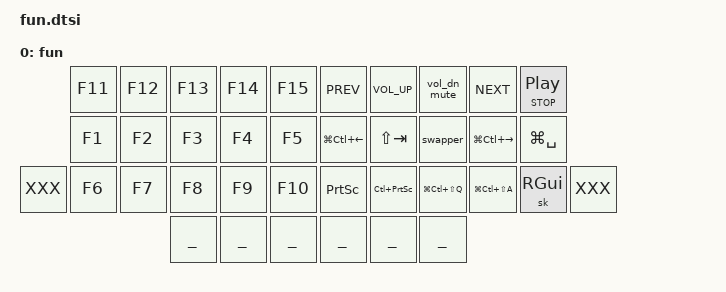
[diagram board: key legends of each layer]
/**
 * Function / System Layer
 */

// Misc aliases
#define DSK_MGR  &kp LG(SPACE)
#define DSK_PREV &kp LG(LC(LEFT))
#define DSK_NEXT &kp LG(LC(RIGHT))
#define PIN_WIN  &kp LG(LC(LS(Q)))
#define PIN_APP  &kp LG(LC(LS(A)))

/ {
    keymap {
        compatible = "zmk,keymap";
  
        fun {
            display-name = "fun";
            bindings = <
//                ╭─────────────┬─────────────┬─────────────┬─────────────┬─────────────╮   ╭─────────────┬─────────────┬─────────────┬─────────────┬─────────────╮
                   &kp F11       &kp F12       &kp F13       &kp F14       &kp F15           &kp C_PREV    &kp C_VOL_UP  &vol_dn_mute  &kp C_NEXT    &mt C_STOP C_PP
//                ├─────────────┼─────────────┼─────────────┼─────────────┼─────────────┤   ├─────────────├─────────────┼─────────────┼─────────────┼─────────────┤
                   &kp F1        &kp F2        &kp F3        &kp F4        &kp F5            DSK_PREV      &kp LS(TAB)   &swapper      DSK_NEXT      DSK_MGR
//  ╭─────────────┬─────────────┼─────────────┼─────────────┼─────────────┼─────────────┤   ├─────────────├─────────────┼─────────────┼─────────────┼─────────────┬─────────────╮
     XXX           &kp F6        &kp F7        &kp F8        &kp F9        &kp F10           &kp PSCRN     &kp LC(PSCRN) PIN_WIN       PIN_APP       &sk RGUI      XXX
//  ╰─────────────┴─────────────┴─────────────┼─────────────┼─────────────┼─────────────┤   ├─────────────├─────────────┼─────────────┼─────────────┴─────────────┴─────────────╯
                                               ___           ___           ___               ___           ___           ___
//                                            ╰─────────────┴─────────────┴─────────────╯   ╰─────────────┴─────────────┴─────────────╯
            >;
		};
	};
};
